# A31M22x register map
Vendor: ABOV Semiconductor Co., Ltd.; File version: 1.0
ARM 32-bit Cortex-M0+ Microcontroller based device, CPU clock up to 75MHz, etc.
CPU: CM0PLUS r0p1, little endian, no MPU, no FPU, VTOR, 2 interrupt priority bits
Registers are 32-bit, read-write, reset 0x0 unless marked. A register's access mark holds for its fields unless they carry their own. Offsets are from the block's base; lines under a group give offsets from that group; [hi:lo] are bit positions; {n}, {i} and the like mark numbered series; 'fields as' and 'values as' point back to an identical list; <NAME> marks a mode.

## Memory map
0x40000000 SCU size 0x100 — System Control Unit
0x40000200 WDT size 0x100 — WATCH-DOG TIMER
0x40000400 DMA0 size 0x10 — Direct Memory Access Control 0
0x40000410 DMA1 size 0x10 — Direct Memory Access Control 1
0x40000420 DMA2 size 0x10 — Direct Memory Access Control 2
0x40000430 DMA3 size 0x10 — Direct Memory Access Control 3
0x40000600 FRT size 0x100 — Free Run Timer
0x40003000 TIMER0 size 0x40 — TIMER COUNTER 0
0x40003040 TIMER1 size 0x40 — TIMER COUNTER 1
0x40003080 TIMER2 size 0x40 — TIMER COUNTER 2
0x400030C0 TIMER3 size 0x40 — TIMER COUNTER 3
0x40008000 UART0 size 0x100 — Universal Asynchronous Receiver/Transmitter 0
0x40008100 UART1 size 0x100 — Universal Asynchronous Receiver/Transmitter 1
0x40009000 SPI size 0x100 — Serial Peripheral Interface Bus
0x4000A000 I2C size 0x100 — Inter-Integrated Circuit
0x4000B300 OPAMP size 0x10
0x4000B380 CMP size 0x40 — Comparator
0x4000F000 CHIPCONFIG size 0x10 — Chip Configuration
0x41000000 CFMC size 0x1000 — CODE FLASH MEMORY CONTROLLER
0x41002000 CRC size 0x1000 — CYCLIC REDUNDANCY CHECK AND CHECKSUM
0x41003000 SRAM size 0x1000 — SRAM MEMORY CONTROLLER
0x42000000 PA size 0x100 — General Port A
0x42000100 PB size 0x100 — General Port B
0x42000200 PC size 0x100 — General Port C
0x42000300 PD size 0x100 — General Port D
0x42000FF0 PORTEN size 0xF — Port Access Enable Register
0x42001000 MPWM size 0x100 — Motor Pulse Width Modulation
0x42002000 ADC size 0x100 — 12-BIT A/D CONVERTER

## Interrupts
0 LVI (SCU)
1 SYSCLKFAIL (SCU)
2 HSEFAIL (SCU)
3 LSEFAIL (SCU)
4 WDT
5 FRT
6 CFMC
7 TIMER0
8 TIMER1
9 TIMER2
10 TIMER3
11 GPIOA (PA)
12 GPIOB (PB)
13 GPIOC (PC)
14 GPIOD (PD)
15 MPWMPRT (MPWM)
16 MPWMOVC (MPWM)
17 MPWM
18 SPI
19 I2C
20 UART0
21 UART1
22 ADC
23 CRC
24 SRAM
25 CMP

## CHIPCONFIG — Chip Configuration
Base 0x4000F000
0x00 VENDORID ro reset 0x41424F56
0x04 CHIPID ro
0x08 REVNR ro — Revision Number Register

## PA — General Port A
Base 0x42000000
Same registers: PB 0x42000100, PC 0x42000200, PD 0x42000300
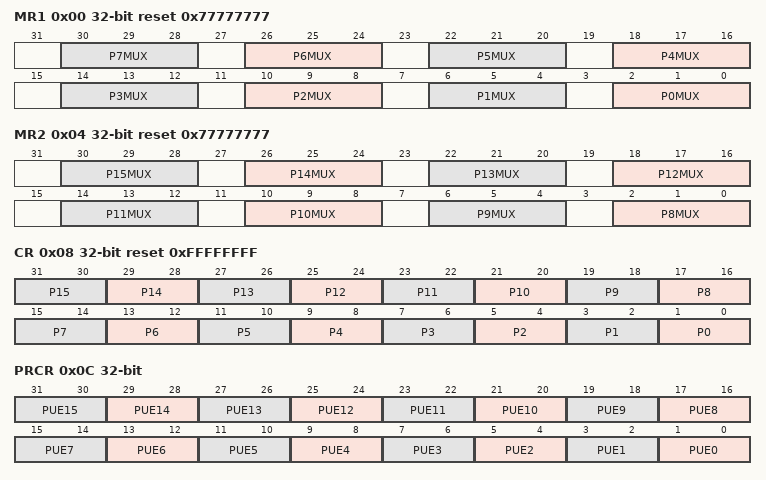
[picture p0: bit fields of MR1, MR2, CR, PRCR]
0x00 MR1 reset 0x77777777 — Port n MUX Control Register 1
  [4n+2:4n] P{n}MUX (n=0..7) — Pin {n} Mode selection bits
0x04 MR2 reset 0x77777777 — Port n MUX Control Register 2
  [4n-30:4n-32] P{n}MUX (n=8..15) — Pin {n} Mode selection bits
0x08 CR reset 0xFFFFFFFF — Port n Type Control Register
  [2n+1:2n] P{n} (n=0..15) — Pin {n} Type selection bit
0x0C PRCR — Port n Pull-up/Pull-down Selection Register
  [2n+1:2n] PUE{n} (n=0..15) — Pin {n} Pull-up/down selection bits
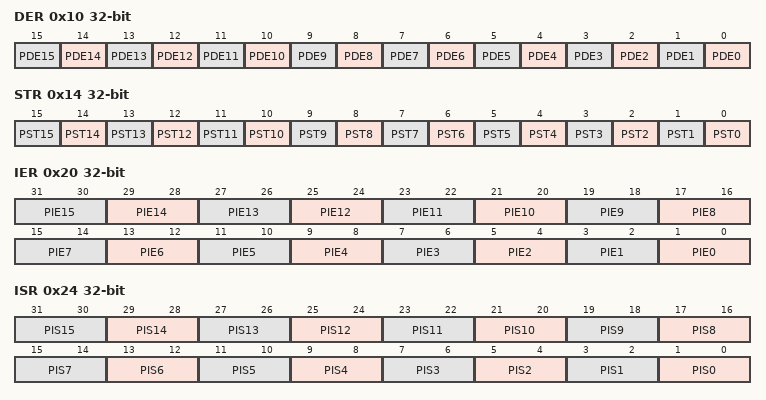
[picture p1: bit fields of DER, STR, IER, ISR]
0x10 DER — Port n Debounce Enable Register
  [n] PDE{n} (n=0..15) — Pin {n} Debounce Enable bits
0x14 STR — Port n Strength Configuraiton Register
  [n] PST{n} (n=0..15) — Pin {n} Strength Enable bits
0x20 IER — Port n Interrupt Enable Register
  [2n+1:2n] PIE{n} (n=0..15) — Pin {n} Interrupt Enable bit
0x24 ISR — Port n Interrupt Status Register
  [2n+1:2n] PIS{n} (n=0..15) — Pin {n} Interrupt Status bit
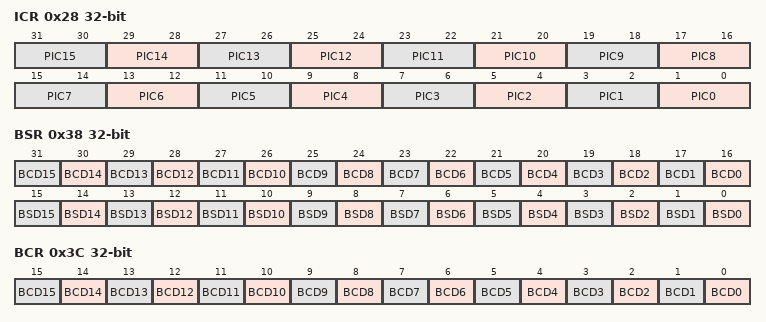
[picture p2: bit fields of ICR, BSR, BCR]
0x28 ICR — Port n Interrupt Control Register
  [2n+1:2n] PIC{n} (n=0..15) — Pin {n} Interrupt Control bit
0x30 ODR — Port n Output Data Register
  [15:0] POD — Pin Output Data bit
0x34 IDR ro — Port n Input Data Register
  [15:0] PID — Port Input Data bits
0x38 BSR wo — Port n Bit Set/Reset Register
  [n+16] BCD{n} (n=0..15) — Port {n} Output Clear bits
  [n] BSD{n} (n=0..15) — Port {n} Output Set bits
0x3C BCR wo — Port n Bit Reset Register
  [n] BCD{n} (n=0..15) — Port {n} Output Clear bits

## Licence text in the file
ARM Limited (ARM) is supplying this software for use with Cortex-M processor based microcontroller, but can be equally used for other suitable processor architectures. This file can be freely distributed. Modifications to this file shall be clearly marked. . THIS SOFTWARE IS PROVIDED "AS IS". NO WARRANTIES, WHETHER EXPRESS, IMPLIED. OR STATUTORY, INCLUDING, BUT NOT LIMITED TO, IMPLIED WARRANTIES OF. MERCHANTABILITY AND FITNESS FOR A PARTICULAR PURPOSE APPLY TO THIS SOFTWARE. ARM SHALL NOT, IN ANY CIRCUMSTANCES, BE LIABLE FOR SPECIAL, INCIDENTAL, OR. CONSEQUENTIAL DAMAGES, FOR ANY REASON WHATSOEVER.

## Notices in the file
Copyright (C) 2012-2014 ARM Limited. All rights reserved.
Purpose: System Viewer Description (SVD) Example (Schema Version 1.1)
This is a description of a none-existent and incomplete device
for demonstration purposes only.
Redistribution and use in source and binary forms, with or without
modification, are permitted provided that the following conditions are met:
- Redistributions of source code must retain the above copyright
notice, this list of conditions and the following disclaimer.
- Redistributions in binary form must reproduce the above copyright
notice, this list of conditions and the following disclaimer in the
documentation and/or other materials provided with the distribution.
- Neither the name of ARM nor the names of its contributors may be used
to endorse or promote products derived from this software without
specific prior written permission.
THIS SOFTWARE IS PROVIDED BY THE COPYRIGHT HOLDERS AND CONTRIBUTORS "AS IS"
AND ANY EXPRESS OR IMPLIED WARRANTIES, INCLUDING, BUT NOT LIMITED TO, THE
ARE DISCLAIMED. IN NO EVENT SHALL COPYRIGHT HOLDERS AND CONTRIBUTORS BE
LIABLE FOR ANY DIRECT, INDIRECT, INCIDENTAL, SPECIAL, EXEMPLARY, OR
CONSEQUENTIAL DAMAGES (INCLUDING, BUT NOT LIMITED TO, PROCUREMENT OF
SUBSTITUTE GOODS OR SERVICES; LOSS OF USE, DATA, OR PROFITS; OR BUSINESS
INTERRUPTION) HOWEVER CAUSED AND ON ANY THEORY OF LIABILITY, WHETHER IN
CONTRACT, STRICT LIABILITY, OR TORT (INCLUDING NEGLIGENCE OR OTHERWISE)
ARISING IN ANY WAY OUT OF THE USE OF THIS SOFTWARE, EVEN IF ADVISED OF THE
POSSIBILITY OF SUCH DAMAGE.
